# myChip register map
Vendor: ARM Ltd.; Series: ARMCM3; File version: 1.2
CPU: CM3 r2p1, little endian, no MPU, no FPU, 3 interrupt priority bits
Registers are 32-bit, read-write, reset 0x0 unless marked. A register's access mark holds for its fields unless they carry their own. Offsets are from the block's base; [hi:lo] are bit positions; {n}, {i} and the like mark numbered series.

## ADC0
Base 0x40038000
Same registers: ADC1 0x40038400, ADC2 0x40038800, ADC3 0x40038C00
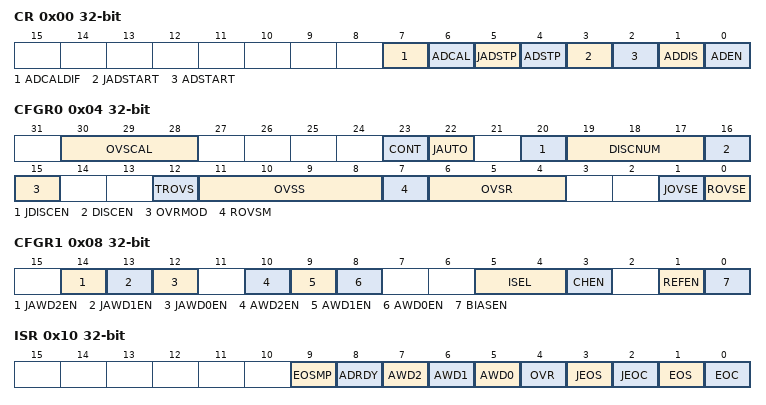
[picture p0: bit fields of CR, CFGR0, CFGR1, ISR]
0x00 CR — ADC Control Register
  [7] ADCALDIF — ADC 校准模式选择
  [6] ADCAL — ADC 启动校准命令
  [5] JADSTP — ADC 停止注入转换命令
  [4] ADSTP — ADC 停止常规转换命令
  [3] JADSTART — ADC 开始注入转换命令
  [2] ADSTART — ADC 开始常规转换命令
  [1] ADDIS — ADC 停止模块使能命令
  [0] ADEN — ADC 开始模块使能命令
0x04 CFGR0 — ADC Configuration Register0
  [30:28] OVSCAL — 自动校准数据叠加比率
  [23] CONT — 常规序列的单次／连续转换模式
  [22] JAUTO — 注入序列自动转换
  [20] JDISCEN — 注入序列的不连续采样模式
  [19:17] DISCNUM — 不连续采样模式通道计数
  [16] DISCEN — 常规序列的单次／不连续转换模式
  [15] OVRMOD — 数据溢出模式
  [12] TROVS — 触发式规则序列过采样使能
  [11:8] OVSS — 过采样数据移位位数
  [7] ROVSM — 常规通道的过采样模式
  [6:4] OVSR — 过采样数据叠加比率
  [1] JOVSE — 注入序列过采样使能
  [0] ROVSE — 规则序列过采样使能
0x08 CFGR1 — ADC Configuration Register1
  [14] JAWD2EN — 模拟看门狗 2 监测注入序列
  [13] JAWD1EN — 模拟看门狗 1 监测注入序列
  [12] JAWD0EN — 模拟看门狗 0 监测注入序列
  [10] AWD2EN — 模拟看门狗 2 监测规则序列
  [9] AWD1EN — 模拟看门狗 1 监测规则序列
  [8] AWD0EN — 模拟看门狗 0 监测规则序列
  [5:4] ISEL — 偏置电流档位
  [3] CHEN — 通道使能
  [1] REFEN — Reference模块使能
  [0] BIASEN — 内部偏置模块使能
0x10 ISR — ADC Interrupt Status Register
  [9] EOSMP — 采样阶段结束中断标志
  [8] ADRDY — ADC 就绪中断标志
  [7] AWD2 — 模拟看门狗 2 中断标志
  [6] AWD1 — 模拟看门狗 1 中断标志
  [5] AWD0 — 模拟看门狗 0 中断标志
  [4] OVR — ADC 数据溢出中断标志
  [3] JEOS — 注入序列结束中断标志
  [2] JEOC — 注入转换结束中断标志
  [1] EOS — 常规序列结束中断标志
  [0] EOC — 常规转换结束中断标志
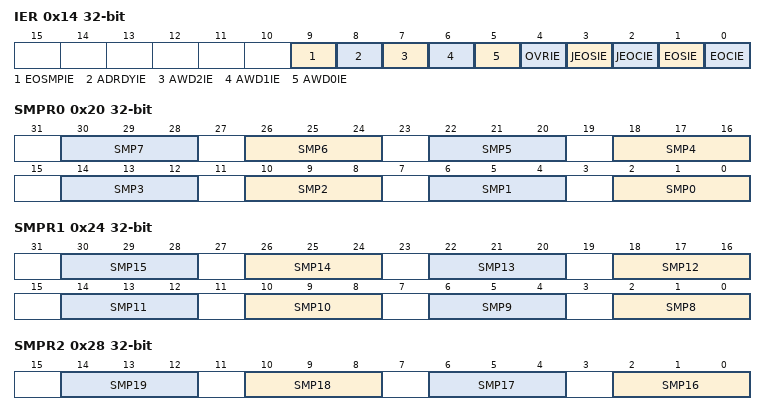
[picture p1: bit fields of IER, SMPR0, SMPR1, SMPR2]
0x14 IER — ADC Interrupt Enable Register
  [9] EOSMPIE — 采样阶段结束中断使能
  [8] ADRDYIE — ADC 就绪中断使能
  [7] AWD2IE — 模拟看门狗 2 中断使能
  [6] AWD1IE — 模拟看门狗 1 中断使能
  [5] AWD0IE — 模拟看门狗 0 中断使能
  [4] OVRIE — ADC 数据溢出中断使能
  [3] JEOSIE — 注入序列结束中断使能
  [2] JEOCIE — 注入转换结束中断使能
  [1] EOSIE — 常规序列结束中断使能
  [0] EOCIE — 常规转换结束中断使能
0x18 SIGSEL — ADC Single-End Select Register
  [19:0] SIGSEL — ADC 通道转换模式选择
0x20 SMPR0 — ADC Sample Time Register 0
  [4n+2:4n] SMP{n} (n=0..7) — 通道 {n} 采样时间选择位
0x24 SMPR1 — ADC Sample Time Register 1
  [4n-30:4n-32] SMP{n} (n=8..15) — 通道 {n} 采样时间选择位
0x28 SMPR2 — ADC Sample Time Register 2
  [4n-62:4n-64] SMP{n} (n=16..19) — 通道 {n} 采样时间选择位
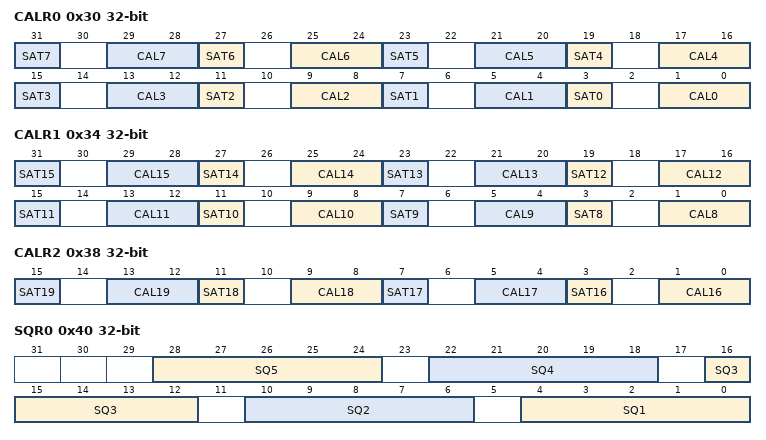
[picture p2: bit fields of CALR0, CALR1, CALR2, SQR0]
0x30 CALR0 — ADC Calibration Data Register 0
  [4n+3] SAT{n} (n=0..7) — 通道 {n} 饱和运算选择位
  [4n+1:4n] CAL{n} (n=0..7) — 通道 {n} 校准系数选择位
0x34 CALR1 — ADC Calibration Data Register 1
  [4n-29] SAT{n} (n=8..15) — 通道 {n} 饱和运算选择位
  [4n-31:4n-32] CAL{n} (n=8..15) — 通道 {n} 校准系数选择位
0x38 CALR2 — ADC Calibration Data Register 2
  [4n-61] SAT{n} (n=16..19) — 通道 {n} 饱和运算选择位
  [4n-63:4n-64] CAL{n} (n=16..19) — 通道 {n} 校准系数选择位
0x40 SQR0 — ADC Regular Sequence Register0
  [6n-2:6n-6] SQ{n} (n=1..5) — 常规序列中的第 {n} 次转换
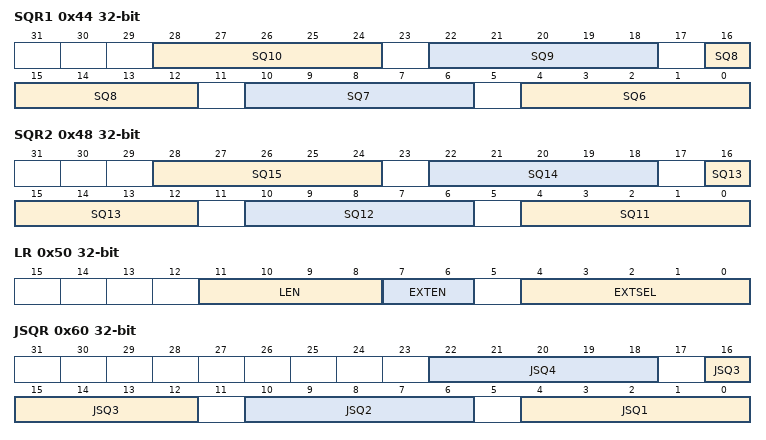
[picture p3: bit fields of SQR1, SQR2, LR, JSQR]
0x44 SQR1 — ADC Regular Sequence Register1
  [6n-32:6n-36] SQ{n} (n=6..10) — 常规序列中的第 {n} 次转换
0x48 SQR2 — ADC Regular Sequence Register2
  [6n-62:6n-66] SQ{n} (n=11..15) — 常规序列中的第 {n} 次转换
0x4C SQR3 — ADC Regular Sequence Register3
  [4:0] SQ16 — 常规序列中的第 16 次转换
0x50 LR — ADC Regular Length Register
  [11:8] LEN — 常规序列的长度
  [7:6] EXTEN — 常规序列的硬件触发使能和极性选择
  [4:0] EXTSEL — 常规序列的硬件触发选择
0x54 DR — ADC Regular Data Register
  [15:0] RDATA — 常规序列已转换的数据
0x58 MAXDR — ADC Maximum Regular Data Register
  [15:0] MAXDATA — 常规序列数据饱和运算最大值（在通道配置为支持饱和运算时有效）
0x5C MINDR — ADC Minimum Regular Data Register
  [15:0] MINDATA — 常规序列数据饱和运算最小值（在通道配置为支持饱和运算时有效）
0x60 JSQR — ADC Injected Sequence Register
  [6n-2:6n-6] JSQ{n} (n=1..4) — 注入序列中的第 {n} 次转换
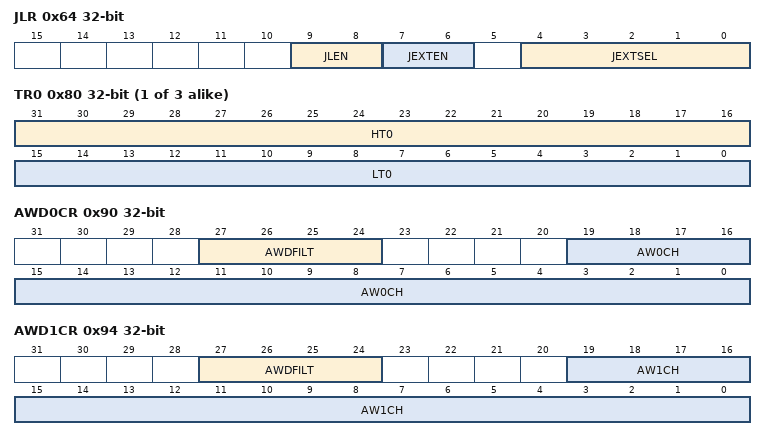
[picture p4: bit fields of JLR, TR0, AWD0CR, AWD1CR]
0x64 JLR — ADC Injected Length Register
  [9:8] JLEN — 注入序列的长度
  [7:6] JEXTEN — 注入序列的硬件触发使能和极性选择
  [4:0] JEXTSEL — 注入序列的硬件触发选择
0x68 MAXJDR — ADC Maximum Injected Data Register
  [15:0] MAXDATA — 注入序列数据饱和运算最大值（在通道配置为支持饱和运算时有效）
0x6C MINJDR — ADC Minimum Injected Data Register
  [15:0] MINDATA — 注入序列数据饱和运算最小值（在通道配置为支持饱和运算时有效）
{0x70+4i} JDR{i} (i=0..3) — ADC Injected Data Register{i}
  [15:0] JDATA — 注入序列的第 {i} 个已转换数据
{0x80+4i} TR{i} (i=0..2) — ADC Watchdog{i} Threshold Register
  [31:16] HT{i} — 模拟看门狗 {i} 阈值上限
  [15:0] LT{i} — 模拟看门狗 {i} 阈值下限
0x90 AWD0CR — ADC Watchdog0 Control Register
  [27:24] AWDFILT — 模拟看门狗 0 滤波点数
  [19:0] AW0CH — 模拟看门狗 0 通道选择
0x94 AWD1CR — ADC Watchdog1 Control Register
  [27:24] AWDFILT — 模拟看门狗 1 滤波点数
  [19:0] AW1CH — 模拟看门狗 1 通道选择
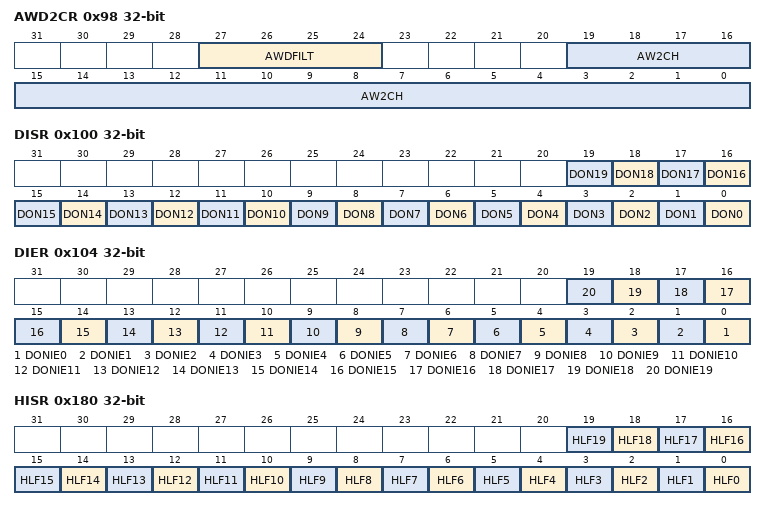
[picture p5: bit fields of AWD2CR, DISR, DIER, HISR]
0x98 AWD2CR — ADC Watchdog 2 Control Register
  [27:24] AWDFILT — 模拟看门狗 2 滤波点数
  [19:0] AW2CH — 模拟看门狗 2 通道选择
{0xA0+4i} OFR{i} (i=0..3) — ADC Offset Register{i}
  [15:0] OFFSET — 第 {i} 组 ADC 偏置补偿系数
{0xC0+4i} GCR{i} (i=0..3) — ADC Gain Coeff Register{i}
  [14:0] COEFF — 第 {i} 组 ADC 增益补偿系数
0x100 DISR — ADC Data Interrupt Status Register
  [n] DON{n} (n=0..19) — 常规序列通道 {n} 转换完成中断标志
0x104 DIER — ADC Data Interrupt Enable Register
  [n] DONIE{n} (n=0..19) — 常规序列通道 {n} 转换完成中断使能
{0x110+4i} CDR{i} (i=0..19) — ADC Channel Data Register{i}
  [15:0] CDATA ro — 常规序列通道 {i} ADC 转换数据结果
0x180 HISR — ADC Half Interrupt Status Register
  [n] HLF{n} (n=0..19) — 通道 {n} DMA传输半完成中断标志
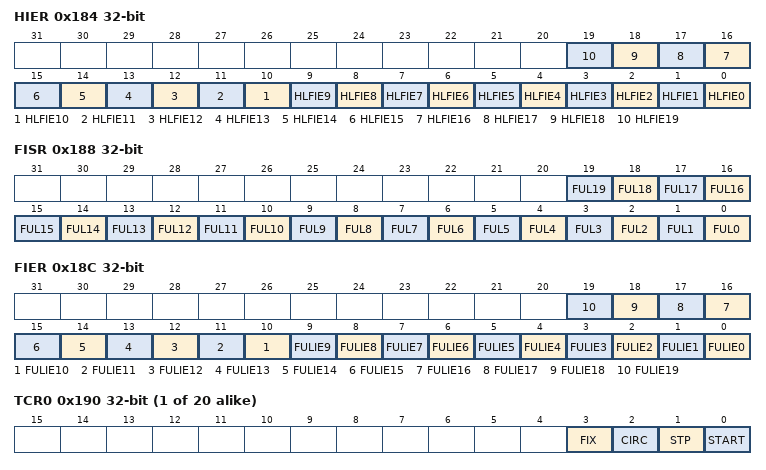
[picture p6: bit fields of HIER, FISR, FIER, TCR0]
0x184 HIER — ADC Half Interrupt Enable Register
  [n] HLFIE{n} (n=0..19) — 通道 {n} DMA 传输半完成中断使能
0x188 FISR — ADC Full Interrupt Status Register
  [n] FUL{n} (n=0..19) — 通道 {n} DMA 传输完成中断标志
0x18C FIER — ADC Full Interrupt Enable Register
  [n] FULIE{n} (n=0..19) — 通道 {n} DMA 传输完成中断使能
{0x190+0x10*i} TCR{i} (i=0..19) — ADC Transfer Control Register{i}
  [3] FIX — DMA固定地址选择位
  [2] CIRC — DMA循环模式选择位
  [1] STP — DMA模式停止位
  [0] START — DMA模式启动位
{0x194+0x10*i} TAR{i} (i=0..19) — ADC Transfer Address Register{i}
  [31:0] ADDR — 通道 {i} DMA 传输的首地址
{0x198+0x10*i} TLR{i} (i=0..19) — ADC Transfer Length Register{i}
  [15:0] LENG — 通道 {i} DMA 传输的长度（单位为 byte）
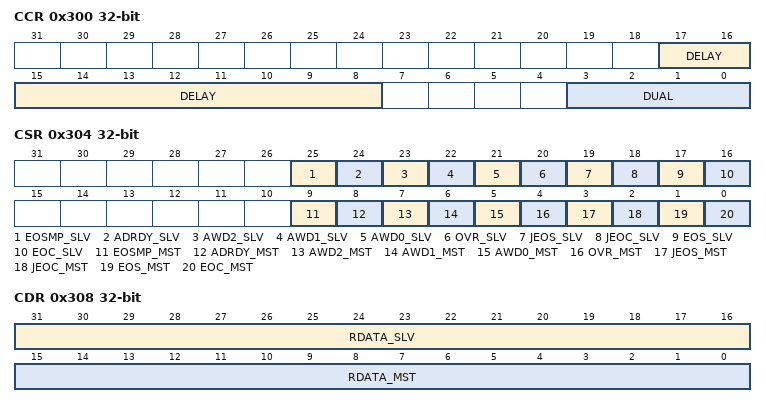
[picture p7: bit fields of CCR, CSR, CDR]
0x300 CCR — ADC Common Control Registe
  [17:8] DELAY — ADC DUAL采样相位延迟（仅主ADC配置有效）
  [3:0] DUAL — ADC DUAL模式选择（仅主ADC配置有效）
0x304 CSR — ADC Common Status Register
  [25] EOSMP_SLV ro — 采样阶段结束中断标志（仅主ADC读取有效）
  [24] ADRDY_SLV ro — ADC 就绪中断标志（仅主ADC读取有效）
  [23] AWD2_SLV ro — 模拟看门狗 2 中断标志（仅主ADC读取有效）
  [22] AWD1_SLV ro — 模拟看门狗 1 中断标志（仅主ADC读取有效）
  [21] AWD0_SLV ro — 模拟看门狗 0 中断标志（仅主ADC读取有效）
  [20] OVR_SLV ro — ADC 数据溢出中断标志（仅主ADC读取有效）
  [19] JEOS_SLV ro — 注入序列结束中断标志（仅主ADC读取有效）
  [18] JEOC_SLV ro — 注入转换结束中断标志（仅主ADC读取有效）
  [17] EOS_SLV ro — 常规序列结束中断标志（仅主ADC读取有效）
  [16] EOC_SLV ro — 常规转换结束中断标志（仅主ADC读取有效）
  [9] EOSMP_MST ro — 采样阶段结束中断标志（仅主ADC读取有效）
  [8] ADRDY_MST ro — ADC 就绪中断标志（仅主ADC读取有效）
  [7] AWD2_MST ro — 模拟看门狗 2 中断标志（仅主ADC读取有效）
  [6] AWD1_MST ro — 模拟看门狗 1 中断标志（仅主ADC读取有效）
  [5] AWD0_MST ro — 模拟看门狗 0 中断标志（仅主ADC读取有效）
  [4] OVR_MST ro — ADC 数据溢出中断标志（仅主ADC读取有效）
  [3] JEOS_MST ro — 注入序列结束中断标志（仅主ADC读取有效）
  [2] JEOC_MST ro — 注入转换结束中断标志（仅主ADC读取有效）
  [1] EOS_MST ro — 常规序列结束中断标志（仅主ADC读取有效）
  [0] EOC_MST ro — 常规转换结束中断标志（仅主ADC读取有效）
0x308 CDR — ADC Common Regular Data Register
  [31:16] RDATA_SLV ro — Slave ADC 常规序列已转换的数据（仅主ADC读取有效）
  [15:0] RDATA_MST ro — 主ADC 常规序列已转换的数据（仅主ADC读取有效）
